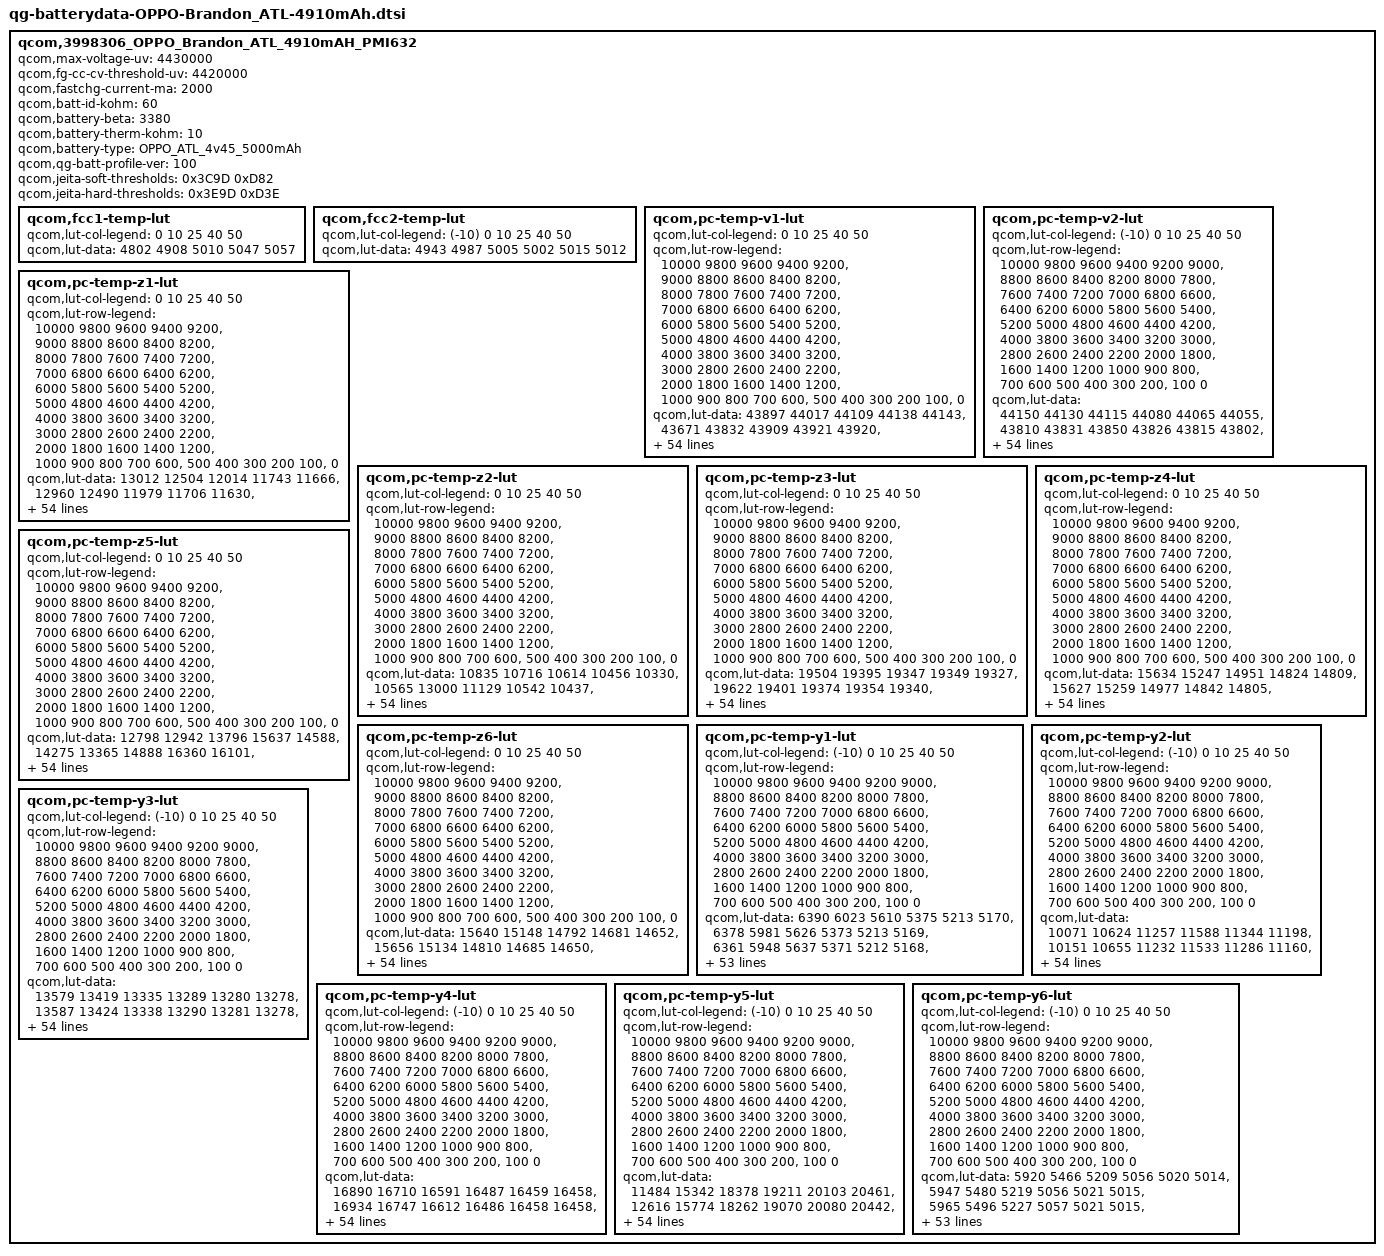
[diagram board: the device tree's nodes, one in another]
qcom,3998306_OPPO_Brandon_ATL_4910mAH_PMI632 {
    /* 3998306_OPPO_Brandon_ATL_4910mAH_PMI632_averaged_MasterSlave_May21th2019 */
    qcom,max-voltage-uv = <4430000>; //4430000
    qcom,fg-cc-cv-threshold-uv = <4420000>; //4420000
    qcom,fastchg-current-ma = <2000>;
    qcom,batt-id-kohm = <60>; // (68|300) + 5.1
    qcom,battery-beta = <3380>;
    qcom,battery-therm-kohm = <10>;
    qcom,battery-type = "OPPO_ATL_4v45_5000mAh";
    qcom,qg-batt-profile-ver = <100>;

    ////From the attached of 80-p3255-39_a
	qcom,jeita-soft-thresholds = <0x3C9D 0xD82>; //disable in kernel
	qcom,jeita-hard-thresholds = <0x3E9D 0xD3E>; //<(-8) 58>;Use SW disable,also Enable in kernel

	qcom,fcc1-temp-lut {
		qcom,lut-col-legend = <0 10 25 40 50>;
		qcom,lut-data = <4802 4908 5010 5047 5057>;
	};

	qcom,fcc2-temp-lut {
		qcom,lut-col-legend = <(-10) 0 10 25 40 50>;
		qcom,lut-data = <4943 4987 5005 5002 5015 5012>;
	};

	qcom,pc-temp-v1-lut {
		qcom,lut-col-legend = <0 10 25 40 50>;
		qcom,lut-row-legend = <10000 9800 9600 9400 9200>,
			<9000 8800 8600 8400 8200>,
			<8000 7800 7600 7400 7200>,
			<7000 6800 6600 6400 6200>,
			<6000 5800 5600 5400 5200>,
			<5000 4800 4600 4400 4200>,
			<4000 3800 3600 3400 3200>,
			<3000 2800 2600 2400 2200>,
			<2000 1800 1600 1400 1200>,
			<1000 900 800 700 600>,
			<500 400 300 200 100>,
			<0>;
		qcom,lut-data = <43897 44017 44109 44138 44143>,
			<43671 43832 43909 43921 43920>,
			<43440 43612 43712 43714 43713>,
			<43208 43382 43495 43507 43506>,
			<42974 43145 43268 43290 43291>,
			<42738 42901 43030 43063 43068>,
			<42501 42660 42789 42830 42839>,
			<42267 42421 42548 42595 42605>,
			<42037 42185 42309 42357 42367>,
			<41812 41951 42072 42119 42130>,
			<41593 41721 41838 41884 41895>,
			<41379 41497 41609 41651 41663>,
			<41167 41278 41383 41423 41437>,
			<40962 41070 41163 41199 41214>,
			<40761 40871 40951 40985 40997>,
			<40562 40678 40746 40779 40787>,
			<40364 40481 40549 40580 40584>,
			<40181 40289 40360 40389 40392>,
			<40017 40112 40176 40204 40206>,
			<39861 39956 40004 40027 40028>,
			<39704 39781 39836 39859 39862>,
			<39548 39536 39629 39668 39676>,
			<39379 39264 39346 39410 39430>,
			<39165 39067 39105 39162 39185>,
			<38949 38919 38969 39008 39023>,
			<38798 38803 38865 38895 38904>,
			<38686 38712 38765 38786 38790>,
			<38598 38637 38667 38677 38677>,
			<38531 38561 38575 38575 38572>,
			<38475 38488 38484 38481 38476>,
			<38424 38421 38400 38394 38389>,
			<38375 38360 38327 38315 38311>,
			<38331 38304 38261 38244 38241>,
			<38293 38253 38202 38178 38174>,
			<38259 38209 38152 38116 38105>,
			<38223 38167 38104 38057 38036>,
			<38188 38127 38056 37998 37967>,
			<38146 38086 38010 37940 37899>,
			<38080 38024 37948 37870 37819>,
			<37988 37930 37858 37776 37717>,
			<37883 37819 37751 37666 37600>,
			<37761 37696 37634 37548 37479>,
			<37621 37556 37499 37416 37347>,
			<37455 37387 37340 37260 37189>,
			<37310 37239 37191 37122 37054>,
			<37208 37134 37087 37032 36974>,
			<37167 37101 37060 37002 36947>,
			<37138 37083 37037 36984 36926>,
			<37104 37057 37016 36959 36898>,
			<37043 36991 36945 36874 36799>,
			<36816 36722 36668 36574 36486>,
			<36375 36275 36227 36129 36040>,
			<35799 35686 35651 35555 35463>,
			<35008 34873 34861 34768 34676>,
			<33707 33547 33627 33539 33445>,
			<30000 30000 30000 30000 30000>;
	};

	qcom,pc-temp-v2-lut {
		qcom,lut-col-legend = <(-10) 0 10 25 40 50>;
		qcom,lut-row-legend = <10000 9800 9600 9400 9200 9000>,
			<8800 8600 8400 8200 8000 7800>,
			<7600 7400 7200 7000 6800 6600>,
			<6400 6200 6000 5800 5600 5400>,
			<5200 5000 4800 4600 4400 4200>,
			<4000 3800 3600 3400 3200 3000>,
			<2800 2600 2400 2200 2000 1800>,
			<1600 1400 1200 1000 900 800>,
			<700 600 500 400 300 200>,
			<100 0>;
		qcom,lut-data = <44150 44130 44115 44080 44065 44055>,
			<43810 43831 43850 43826 43815 43802>,
			<43502 43554 43596 43580 43574 43559>,
			<43229 43301 43356 43345 43341 43326>,
			<42991 43074 43131 43121 43119 43105>,
			<42754 42844 42901 42892 42892 42881>,
			<42499 42603 42663 42655 42657 42648>,
			<42245 42359 42421 42414 42418 42411>,
			<42020 42114 42180 42176 42182 42175>,
			<41820 41867 41938 41938 41944 41939>,
			<41611 41624 41702 41705 41711 41707>,
			<41376 41377 41470 41473 41481 41477>,
			<41134 41143 41245 41247 41255 41251>,
			<40913 40954 41027 41028 41036 41032>,
			<40709 40794 40815 40815 40822 40818>,
			<40474 40606 40610 40609 40616 40612>,
			<40143 40355 40414 40410 40416 40414>,
			<39796 40089 40213 40217 40223 40223>,
			<39541 39850 39994 40034 40043 40044>,
			<39337 39622 39763 39854 39868 39869>,
			<39145 39404 39535 39646 39665 39668>,
			<38952 39191 39306 39392 39419 39428>,
			<38773 38994 39097 39155 39189 39201>,
			<38610 38817 38920 38971 39002 39014>,
			<38457 38654 38763 38813 38840 38851>,
			<38341 38494 38622 38676 38703 38712>,
			<38257 38326 38493 38556 38584 38593>,
			<38188 38190 38377 38449 38477 38484>,
			<38124 38100 38273 38350 38380 38384>,
			<38065 38031 38176 38258 38289 38290>,
			<38008 37977 38079 38174 38207 38206>,
			<37952 37932 37982 38095 38130 38130>,
			<37896 37889 37905 38021 38056 38055>,
			<37837 37842 37851 37955 37986 37985>,
			<37776 37794 37806 37889 37912 37908>,
			<37714 37743 37763 37815 37822 37806>,
			<37649 37687 37721 37731 37717 37680>,
			<37580 37624 37670 37646 37614 37566>,
			<37503 37553 37603 37562 37516 37469>,
			<37419 37470 37523 37478 37421 37378>,
			<37328 37372 37427 37392 37333 37289>,
			<37226 37258 37314 37299 37244 37195>,
			<37124 37132 37185 37183 37131 37079>,
			<37027 36990 37040 37052 37000 36947>,
			<36936 36848 36876 36921 36885 36834>,
			<36849 36747 36793 36872 36843 36794>,
			<36806 36708 36753 36853 36828 36781>,
			<36759 36675 36720 36831 36812 36763>,
			<36705 36632 36673 36797 36776 36726>,
			<36636 36552 36565 36703 36653 36583>,
			<36501 36345 36298 36401 36321 36229>,
			<36220 35916 35801 35905 35817 35724>,
			<35726 35275 35151 35266 35168 35068>,
			<34966 34334 34262 34402 34268 34160>,
			<33828 32877 32876 32999 32966 32811>,
			<32285 29186 27697 27990 28108 28121>;
	};

	qcom,pc-temp-z1-lut {
		qcom,lut-col-legend = <0 10 25 40 50>;
		qcom,lut-row-legend = <10000 9800 9600 9400 9200>,
			<9000 8800 8600 8400 8200>,
			<8000 7800 7600 7400 7200>,
			<7000 6800 6600 6400 6200>,
			<6000 5800 5600 5400 5200>,
			<5000 4800 4600 4400 4200>,
			<4000 3800 3600 3400 3200>,
			<3000 2800 2600 2400 2200>,
			<2000 1800 1600 1400 1200>,
			<1000 900 800 700 600>,
			<500 400 300 200 100>,
			<0>;
		qcom,lut-data = <13012 12504 12014 11743 11666>,
			<12960 12490 11979 11706 11630>,
			<12955 12465 11961 11693 11620>,
			<12965 12446 11951 11685 11612>,
			<12973 12435 11941 11678 11607>,
			<12960 12426 11930 11672 11603>,
			<12942 12411 11919 11667 11600>,
			<12933 12390 11909 11664 11600>,
			<12926 12377 11900 11661 11601>,
			<12917 12371 11896 11661 11602>,
			<12905 12362 11894 11662 11604>,
			<12890 12344 11892 11663 11605>,
			<12877 12325 11890 11664 11606>,
			<12863 12321 11889 11663 11605>,
			<12851 12322 11889 11663 11606>,
			<12837 12323 11890 11663 11607>,
			<12815 12321 11891 11663 11608>,
			<12802 12319 11892 11664 11609>,
			<12798 12315 11892 11665 11610>,
			<12797 12313 11892 11665 11611>,
			<12801 12315 11893 11666 11611>,
			<12813 12315 11893 11667 11612>,
			<12820 12315 11895 11668 11613>,
			<12814 12317 11897 11669 11615>,
			<12806 12322 11899 11671 11616>,
			<12806 12328 11901 11674 11618>,
			<12814 12334 11904 11677 11621>,
			<12819 12340 11909 11679 11624>,
			<12820 12341 11914 11682 11627>,
			<12822 12337 11918 11686 11629>,
			<12823 12335 11921 11690 11632>,
			<12826 12335 11923 11693 11634>,
			<12830 12337 11925 11696 11637>,
			<12839 12339 11928 11699 11640>,
			<12853 12344 11935 11702 11643>,
			<12862 12350 11941 11706 11646>,
			<12870 12359 11945 11709 11649>,
			<12875 12371 11947 11713 11652>,
			<12879 12377 11950 11716 11654>,
			<12881 12382 11955 11719 11656>,
			<12886 12387 11961 11722 11659>,
			<12908 12390 11969 11725 11661>,
			<12918 12395 11978 11729 11663>,
			<12902 12407 11985 11731 11665>,
			<12921 12414 11992 11733 11668>,
			<12912 12400 11993 11737 11668>,
			<12927 12399 11996 11736 11668>,
			<12929 12407 11995 11736 11669>,
			<12934 12405 12002 11739 11670>,
			<12910 12418 12000 11742 11674>,
			<12961 12420 12005 11746 11677>,
			<12942 12438 12016 11753 11683>,
			<12954 12448 12029 11760 11690>,
			<12983 12480 12054 11773 11699>,
			<12983 12480 12054 11773 11699>,
			<12983 12480 12054 11773 11699>;
	};

	qcom,pc-temp-z2-lut {
		qcom,lut-col-legend = <0 10 25 40 50>;
		qcom,lut-row-legend = <10000 9800 9600 9400 9200>,
			<9000 8800 8600 8400 8200>,
			<8000 7800 7600 7400 7200>,
			<7000 6800 6600 6400 6200>,
			<6000 5800 5600 5400 5200>,
			<5000 4800 4600 4400 4200>,
			<4000 3800 3600 3400 3200>,
			<3000 2800 2600 2400 2200>,
			<2000 1800 1600 1400 1200>,
			<1000 900 800 700 600>,
			<500 400 300 200 100>,
			<0>;
		qcom,lut-data = <10835 10716 10614 10456 10330>,
			<10565 13000 11129 10542 10437>,
			<10459 11886 11760 10548 10369>,
			<10433 11134 11296 10589 10446>,
			<10411 10782 10971 10611 10515>,
			<10378 10572 10762 10594 10526>,
			<10345 10527 10642 10565 10518>,
			<10325 10503 10621 10538 10492>,
			<10308 10486 10607 10511 10453>,
			<10300 10471 10589 10498 10431>,
			<10332 10463 10569 10493 10421>,
			<10378 10461 10563 10490 10415>,
			<10379 10462 10573 10501 10415>,
			<10336 10475 10587 10522 10422>,
			<10310 10591 10653 10522 10423>,
			<10317 10701 10910 10483 10419>,
			<10328 10683 11051 10450 10411>,
			<10350 10607 10876 10461 10387>,
			<10449 10585 10659 10487 10359>,
			<10540 10600 10644 10484 10362>,
			<10531 10618 10662 10452 10392>,
			<10481 10637 10682 10436 10414>,
			<10463 10652 10709 10490 10422>,
			<10468 10649 10722 10554 10431>,
			<10474 10620 10703 10549 10494>,
			<10481 10600 10675 10520 10712>,
			<10490 10607 10681 10522 10850>,
			<10499 10621 10729 10652 10869>,
			<10504 10626 10758 10760 10820>,
			<10509 10627 10756 10732 10716>,
			<10516 10629 10750 10659 10580>,
			<10524 10632 10740 10607 10464>,
			<10532 10637 10721 10566 10344>,
			<10539 10643 10710 10543 10284>,
			<10546 10653 10714 10542 10307>,
			<10554 10666 10724 10553 10358>,
			<10563 10677 10744 10579 10406>,
			<10574 10689 10780 10637 10459>,
			<10588 10704 10811 10687 10506>,
			<10606 10726 10834 10721 10546>,
			<10622 10743 10853 10749 10579>,
			<10633 10749 10869 10773 10612>,
			<10650 10755 10882 10791 10647>,
			<10693 10775 10890 10799 10704>,
			<10950 10935 10933 10786 10692>,
			<10883 11063 10981 10672 10538>,
			<10860 11058 10937 10650 10553>,
			<10700 11347 10948 10653 10560>,
			<10450 11491 10955 10678 10609>,
			<10429 11570 11090 10746 10612>,
			<10374 11449 11079 10622 10429>,
			<10226 11407 11035 10453 10299>,
			<9978 11225 11042 10407 10256>,
			<9902 10923 10973 10354 10171>,
			<9902 10923 10973 10354 10171>,
			<9902 10923 10973 10354 10171>;
	};

	qcom,pc-temp-z3-lut {
		qcom,lut-col-legend = <0 10 25 40 50>;
		qcom,lut-row-legend = <10000 9800 9600 9400 9200>,
			<9000 8800 8600 8400 8200>,
			<8000 7800 7600 7400 7200>,
			<7000 6800 6600 6400 6200>,
			<6000 5800 5600 5400 5200>,
			<5000 4800 4600 4400 4200>,
			<4000 3800 3600 3400 3200>,
			<3000 2800 2600 2400 2200>,
			<2000 1800 1600 1400 1200>,
			<1000 900 800 700 600>,
			<500 400 300 200 100>,
			<0>;
		qcom,lut-data = <19504 19395 19347 19349 19327>,
			<19622 19401 19374 19354 19340>,
			<19680 19468 19391 19377 19361>,
			<19713 19510 19438 19387 19374>,
			<19730 19542 19458 19395 19382>,
			<19738 19563 19457 19402 19387>,
			<19743 19567 19453 19406 19390>,
			<19744 19568 19453 19407 19393>,
			<19737 19568 19454 19407 19395>,
			<19730 19567 19453 19407 19395>,
			<19731 19566 19447 19403 19392>,
			<19734 19562 19440 19399 19387>,
			<19730 19556 19432 19396 19383>,
			<19716 19552 19426 19393 19380>,
			<19704 19550 19426 19390 19376>,
			<19702 19548 19435 19382 19373>,
			<19701 19541 19439 19375 19370>,
			<19702 19527 19428 19372 19366>,
			<19696 19519 19414 19370 19363>,
			<19685 19514 19411 19367 19359>,
			<19678 19512 19409 19362 19354>,
			<19668 19525 19410 19360 19350>,
			<19667 19547 19418 19362 19349>,
			<19682 19550 19424 19363 19348>,
			<19699 19542 19416 19359 19347>,
			<19701 19533 19401 19347 19352>,
			<19696 19526 19398 19344 19361>,
			<19690 19520 19400 19363 19385>,
			<19683 19520 19405 19385 19402>,
			<19676 19522 19417 19392 19400>,
			<19669 19525 19431 19397 19393>,
			<19664 19526 19433 19397 19386>,
			<19659 19527 19432 19391 19376>,
			<19654 19527 19430 19384 19367>,
			<19649 19525 19426 19378 19359>,
			<19644 19523 19420 19372 19353>,
			<19640 19520 19416 19366 19348>,
			<19636 19515 19412 19362 19345>,
			<19632 19511 19408 19359 19343>,
			<19626 19506 19404 19357 19344>,
			<19620 19501 19400 19355 19344>,
			<19610 19497 19400 19357 19347>,
			<19597 19492 19399 19362 19353>,
			<19577 19484 19395 19363 19359>,
			<19456 19451 19384 19359 19358>,
			<19332 19426 19375 19342 19340>,
			<19325 19423 19370 19341 19331>,
			<19304 19349 19369 19334 19326>,
			<19282 19317 19359 19329 19323>,
			<19281 19307 19344 19328 19327>,
			<19281 19339 19358 19356 19352>,
			<19285 19314 19355 19363 19356>,
			<19291 19309 19333 19356 19352>,
			<19302 19316 19333 19355 19353>,
			<19302 19316 19333 19355 19353>,
			<19302 19316 19333 19355 19353>;
	};

	qcom,pc-temp-z4-lut {
		qcom,lut-col-legend = <0 10 25 40 50>;
		qcom,lut-row-legend = <10000 9800 9600 9400 9200>,
			<9000 8800 8600 8400 8200>,
			<8000 7800 7600 7400 7200>,
			<7000 6800 6600 6400 6200>,
			<6000 5800 5600 5400 5200>,
			<5000 4800 4600 4400 4200>,
			<4000 3800 3600 3400 3200>,
			<3000 2800 2600 2400 2200>,
			<2000 1800 1600 1400 1200>,
			<1000 900 800 700 600>,
			<500 400 300 200 100>,
			<0>;
		qcom,lut-data = <15634 15247 14951 14824 14809>,
			<15627 15259 14977 14842 14805>,
			<15583 15207 14956 14864 14833>,
			<15444 15143 14893 14845 14820>,
			<15302 15068 14860 14823 14804>,
			<15206 15001 14843 14802 14787>,
			<15126 14947 14829 14782 14771>,
			<15065 14902 14809 14765 14755>,
			<15019 14865 14782 14749 14740>,
			<14975 14835 14761 14734 14727>,
			<14925 14810 14745 14721 14717>,
			<14880 14790 14734 14710 14708>,
			<14859 14773 14727 14703 14703>,
			<14847 14755 14721 14696 14698>,
			<14836 14730 14708 14692 14693>,
			<14821 14713 14683 14689 14688>,
			<14804 14717 14670 14687 14684>,
			<14786 14729 14678 14681 14679>,
			<14762 14731 14690 14675 14676>,
			<14745 14722 14691 14674 14675>,
			<14744 14716 14690 14677 14677>,
			<14747 14740 14699 14683 14680>,
			<14752 14788 14765 14739 14731>,
			<14777 14816 14817 14800 14793>,
			<14814 14833 14821 14807 14796>,
			<14829 14840 14821 14807 14780>,
			<14836 14832 14819 14805 14761>,
			<14838 14817 14802 14773 14725>,
			<14833 14802 14779 14735 14695>,
			<14821 14786 14755 14714 14688>,
			<14810 14771 14731 14698 14684>,
			<14799 14760 14718 14689 14681>,
			<14789 14750 14710 14683 14678>,
			<14780 14743 14706 14681 14676>,
			<14771 14738 14704 14681 14675>,
			<14761 14734 14702 14681 14675>,
			<14751 14730 14703 14681 14675>,
			<14742 14726 14704 14683 14675>,
			<14738 14726 14705 14685 14676>,
			<14735 14726 14712 14694 14686>,
			<14732 14726 14717 14703 14697>,
			<14727 14718 14712 14699 14693>,
			<14722 14707 14700 14689 14683>,
			<14718 14700 14697 14689 14682>,
			<14768 14687 14686 14684 14677>,
			<14864 14673 14665 14671 14664>,
			<14869 14670 14660 14665 14664>,
			<14888 14741 14647 14655 14653>,
			<14903 14770 14645 14641 14635>,
			<14895 14777 14659 14641 14631>,
			<14899 14751 14664 14646 14647>,
			<14912 14786 14674 14650 14654>,
			<14917 14796 14701 14659 14660>,
			<14930 14798 14703 14663 14661>,
			<14930 14798 14703 14663 14661>,
			<14930 14798 14703 14663 14661>;
	};

	qcom,pc-temp-z5-lut {
		qcom,lut-col-legend = <0 10 25 40 50>;
		qcom,lut-row-legend = <10000 9800 9600 9400 9200>,
			<9000 8800 8600 8400 8200>,
			<8000 7800 7600 7400 7200>,
			<7000 6800 6600 6400 6200>,
			<6000 5800 5600 5400 5200>,
			<5000 4800 4600 4400 4200>,
			<4000 3800 3600 3400 3200>,
			<3000 2800 2600 2400 2200>,
			<2000 1800 1600 1400 1200>,
			<1000 900 800 700 600>,
			<500 400 300 200 100>,
			<0>;
		qcom,lut-data = <12798 12942 13796 15637 14588>,
			<14275 13365 14888 16360 16101>,
			<15196 14536 15383 17699 17817>,
			<15794 15437 17125 18608 19308>,
			<16278 16557 18339 19549 20489>,
			<16771 17723 19034 20339 21135>,
			<17251 18495 19644 20928 21726>,
			<17607 19149 20341 21344 22526>,
			<17828 19877 21064 21818 23538>,
			<18098 20760 21627 22421 24399>,
			<18795 21675 22020 23251 25081>,
			<19712 22508 22038 24062 25645>,
			<20260 23343 22108 25033 26085>,
			<20630 24489 22413 26082 26465>,
			<21087 26586 24167 26273 26973>,
			<22176 28320 29862 25478 27821>,
			<24276 28380 33051 24820 28817>,
			<26009 27508 30477 25750 30098>,
			<27514 27182 27200 27317 31254>,
			<28392 27763 27387 27684 31372>,
			<28481 29106 28455 27519 30819>,
			<30138 39389 30165 27183 29924>,
			<33137 53688 33282 26448 26972>,
			<43048 54874 35123 25278 23335>,
			<53808 44872 30867 22602 21196>,
			<54636 35515 23347 18271 19482>,
			<50158 31152 21166 16964 19440>,
			<45350 28323 20755 18584 24153>,
			<41829 28012 20734 21029 28881>,
			<38812 28876 23113 23745 29958>,
			<37459 30190 27497 26767 30518>,
			<36728 32170 30895 28719 30366>,
			<36319 34805 33961 30118 28708>,
			<36171 37190 36143 30948 27552>,
			<36097 39660 37766 31431 27653>,
			<36188 41185 38758 31743 27838>,
			<37024 41652 38528 31577 27874>,
			<38227 41834 37421 30613 27782>,
			<39550 41441 35995 29371 27586>,
			<41039 39972 33140 27249 26236>,
			<41440 38566 30657 25477 24795>,
			<38670 37745 30444 25721 25141>,
			<35221 36847 30542 26551 26594>,
			<32662 35525 28666 26893 29501>,
			<22509 31732 28076 26247 30327>,
			<13314 29628 29688 22164 23207>,
			<13063 28271 27838 22344 19754>,
			<12473 16200 29423 21721 20327>,
			<12105 13582 25742 23675 24032>,
			<12133 13292 20278 22877 28764>,
			<12186 15204 21212 27085 28171>,
			<12086 13307 19514 25872 24750>,
			<12036 12958 15331 20607 20524>,
			<12134 13020 14962 18701 18604>,
			<12134 13020 14962 18701 18604>,
			<12134 13020 14962 18701 18604>;
	};

	qcom,pc-temp-z6-lut {
		qcom,lut-col-legend = <0 10 25 40 50>;
		qcom,lut-row-legend = <10000 9800 9600 9400 9200>,
			<9000 8800 8600 8400 8200>,
			<8000 7800 7600 7400 7200>,
			<7000 6800 6600 6400 6200>,
			<6000 5800 5600 5400 5200>,
			<5000 4800 4600 4400 4200>,
			<4000 3800 3600 3400 3200>,
			<3000 2800 2600 2400 2200>,
			<2000 1800 1600 1400 1200>,
			<1000 900 800 700 600>,
			<500 400 300 200 100>,
			<0>;
		qcom,lut-data = <15640 15148 14792 14681 14652>,
			<15656 15134 14810 14685 14650>,
			<15641 15130 14805 14702 14669>,
			<15572 15116 14799 14698 14669>,
			<15495 15084 14791 14694 14669>,
			<15440 15052 14782 14689 14665>,
			<15392 15023 14772 14682 14659>,
			<15351 14994 14761 14675 14654>,
			<15316 14970 14749 14668 14649>,
			<15284 14950 14738 14661 14644>,
			<15256 14933 14727 14654 14638>,
			<15231 14918 14718 14647 14632>,
			<15210 14904 14710 14642 14627>,
			<15191 14891 14704 14638 14623>,
			<15175 14879 14699 14633 14619>,
			<15161 14869 14693 14628 14615>,
			<15149 14865 14689 14623 14611>,
			<15137 14861 14686 14619 14607>,
			<15122 14857 14683 14615 14603>,
			<15109 14850 14682 14613 14601>,
			<15107 14847 14681 14612 14599>,
			<15106 14866 14686 14612 14598>,
			<15106 14898 14719 14637 14619>,
			<15125 14911 14745 14665 14646>,
			<15152 14915 14743 14667 14648>,
			<15160 14916 14737 14662 14644>,
			<15161 14912 14732 14658 14641>,
			<15162 14903 14727 14655 14639>,
			<15158 14897 14723 14652 14636>,
			<15150 14893 14720 14648 14632>,
			<15144 14889 14717 14644 14628>,
			<15138 14886 14714 14640 14623>,
			<15133 14883 14710 14635 14616>,
			<15128 14881 14707 14631 14611>,
			<15124 14879 14705 14627 14607>,
			<15120 14878 14703 14625 14603>,
			<15117 14876 14702 14622 14601>,
			<15115 14875 14700 14620 14599>,
			<15116 14875 14700 14620 14598>,
			<15118 14876 14702 14623 14603>,
			<15120 14876 14704 14627 14608>,
			<15120 14874 14702 14626 14608>,
			<15119 14871 14698 14625 14607>,
			<15116 14869 14696 14625 14610>,
			<15087 14855 14688 14622 14608>,
			<15072 14840 14676 14608 14593>,
			<15071 14838 14672 14605 14589>,
			<15069 14831 14666 14597 14581>,
			<15069 14829 14660 14588 14571>,
			<15071 14831 14661 14588 14572>,
			<15079 14841 14672 14606 14593>,
			<15096 14849 14677 14613 14600>,
			<15113 14858 14681 14615 14603>,
			<15144 14874 14686 14619 14607>,
			<15144 14874 14686 14619 14607>,
			<15144 14874 14686 14619 14607>;
	};

	qcom,pc-temp-y1-lut {
		qcom,lut-col-legend = <(-10) 0 10 25 40 50>;
		qcom,lut-row-legend = <10000 9800 9600 9400 9200 9000>,
			<8800 8600 8400 8200 8000 7800>,
			<7600 7400 7200 7000 6800 6600>,
			<6400 6200 6000 5800 5600 5400>,
			<5200 5000 4800 4600 4400 4200>,
			<4000 3800 3600 3400 3200 3000>,
			<2800 2600 2400 2200 2000 1800>,
			<1600 1400 1200 1000 900 800>,
			<700 600 500 400 300 200>,
			<100 0>;
		qcom,lut-data = <6390 6023 5610 5375 5213 5170>,
			<6378 5981 5626 5373 5213 5169>,
			<6361 5948 5637 5371 5212 5168>,
			<6345 5923 5644 5367 5212 5166>,
			<6334 5908 5647 5364 5211 5165>,
			<6333 5904 5648 5362 5210 5164>,
			<6344 5915 5643 5360 5209 5164>,
			<6355 5929 5637 5358 5208 5164>,
			<6352 5929 5637 5357 5207 5164>,
			<6335 5918 5638 5357 5205 5164>,
			<6326 5909 5638 5357 5205 5164>,
			<6336 5902 5634 5357 5205 5164>,
			<6350 5898 5630 5356 5205 5164>,
			<6354 5900 5629 5355 5205 5165>,
			<6361 5906 5631 5354 5205 5165>,
			<6369 5909 5632 5354 5204 5165>,
			<6365 5903 5633 5356 5205 5165>,
			<6357 5896 5634 5358 5205 5166>,
			<6350 5899 5633 5358 5206 5166>,
			<6326 5910 5631 5357 5206 5166>,
			<6313 5915 5631 5357 5207 5167>,
			<6321 5913 5635 5358 5208 5167>,
			<6331 5910 5638 5359 5208 5168>,
			<6327 5908 5639 5361 5209 5169>,
			<6315 5906 5640 5363 5211 5170>,
			<6310 5908 5642 5365 5212 5172>,
			<6326 5915 5645 5367 5214 5173>,
			<6348 5920 5647 5369 5216 5175>,
			<6349 5924 5646 5373 5217 5176>,
			<6337 5924 5643 5376 5219 5178>,
			<6332 5920 5644 5378 5221 5180>,
			<6340 5909 5653 5380 5224 5182>,
			<6347 5903 5660 5383 5226 5184>,
			<6343 5915 5656 5387 5228 5185>,
			<6331 5935 5650 5392 5230 5187>,
			<6326 5942 5647 5394 5232 5189>,
			<6319 5941 5646 5395 5233 5190>,
			<6312 5936 5645 5395 5234 5191>,
			<6314 5930 5649 5395 5235 5192>,
			<6324 5925 5654 5395 5236 5194>,
			<6330 5927 5660 5399 5237 5194>,
			<6330 5938 5670 5403 5239 5194>,
			<6329 5932 5676 5404 5240 5195>,
			<6352 5922 5676 5407 5241 5196>,
			<6341 5966 5671 5411 5244 5198>,
			<6352 5978 5691 5415 5246 5201>,
			<6356 5977 5687 5417 5248 5200>,
			<6369 5963 5676 5416 5248 5200>,
			<6364 5985 5674 5420 5247 5201>,
			<6348 5954 5693 5417 5247 5202>,
			<6385 5978 5697 5420 5249 5205>,
			<6458 6002 5696 5427 5253 5207>,
			<6553 6069 5723 5439 5257 5212>,
			<6626 6142 5763 5452 5265 5219>,
			<6626 6142 5763 5452 5265 5219>,
			<6626 6142 5763 5452 5265 5219>;
	};

	qcom,pc-temp-y2-lut {
		qcom,lut-col-legend = <(-10) 0 10 25 40 50>;
		qcom,lut-row-legend = <10000 9800 9600 9400 9200 9000>,
			<8800 8600 8400 8200 8000 7800>,
			<7600 7400 7200 7000 6800 6600>,
			<6400 6200 6000 5800 5600 5400>,
			<5200 5000 4800 4600 4400 4200>,
			<4000 3800 3600 3400 3200 3000>,
			<2800 2600 2400 2200 2000 1800>,
			<1600 1400 1200 1000 900 800>,
			<700 600 500 400 300 200>,
			<100 0>;
		qcom,lut-data = <10071 10624 11257 11588 11344 11198>,
			<10151 10655 11232 11533 11286 11160>,
			<10238 10700 11207 11472 11224 11104>,
			<10322 10745 11185 11413 11163 11045>,
			<10392 10782 11163 11364 11112 10996>,
			<10438 10798 11144 11333 11074 10973>,
			<10458 10801 11126 11318 11047 10968>,
			<10475 10801 11110 11307 11026 10964>,
			<10530 10800 11097 11290 11009 10951>,
			<10659 10798 11086 11267 10990 10925>,
			<10728 10803 11082 11253 10980 10915>,
			<10725 10889 11089 11248 10978 10922>,
			<10720 10989 11103 11248 10981 10930>,
			<10732 11000 11131 11260 11000 10925>,
			<10782 10994 11184 11283 11042 10912>,
			<10802 10998 11237 11306 11061 10918>,
			<10354 11066 11295 11345 11079 10972>,
			<9780 11146 11342 11393 11106 11041>,
			<9700 11181 11367 11462 11182 11104>,
			<9694 11204 11385 11545 11307 11171>,
			<9690 11226 11392 11562 11365 11219>,
			<9687 11252 11396 11523 11379 11261>,
			<9684 11270 11400 11488 11376 11276>,
			<9681 11248 11422 11487 11328 11240>,
			<9678 11188 11458 11499 11270 11195>,
			<9675 11153 11476 11522 11277 11195>,
			<9674 11116 11487 11577 11332 11227>,
			<9673 11089 11494 11621 11378 11265>,
			<9672 10911 11502 11638 11434 11308>,
			<9671 10536 11509 11651 11497 11349>,
			<9669 10404 11508 11666 11508 11365>,
			<9668 10349 11501 11696 11495 11370>,
			<9667 10267 11494 11721 11491 11390>,
			<9666 10011 11474 11741 11541 11526>,
			<9666 9746 11440 11756 11600 11671>,
			<9665 9702 11407 11737 11589 11614>,
			<9665 9688 11370 11677 11536 11431>,
			<9664 9680 11322 11645 11491 11364>,
			<9664 9674 11235 11637 11447 11383>,
			<9664 9670 11122 11631 11414 11407>,
			<9663 9667 11018 11626 11423 11357>,
			<9663 9665 10914 11628 11452 11264>,
			<9663 9664 10802 11612 11474 11285>,
			<9662 9663 10647 11558 11393 11284>,
			<9661 9662 10298 11527 11320 11180>,
			<9660 9660 9919 11459 11180 11026>,
			<9660 9660 9887 11451 11179 10996>,
			<9659 9659 9802 11424 11202 11016>,
			<9658 9658 9739 11437 11213 11096>,
			<9656 9657 9699 11420 11205 11021>,
			<9653 9656 9683 11398 11148 10922>,
			<9650 9653 9668 11317 11017 10873>,
			<9649 9650 9659 11207 10942 10787>,
			<9648 9649 9654 11102 10808 10591>,
			<9648 9649 9654 11102 10808 10591>,
			<9648 9649 9654 11102 10808 10591>;
	};

	qcom,pc-temp-y3-lut {
		qcom,lut-col-legend = <(-10) 0 10 25 40 50>;
		qcom,lut-row-legend = <10000 9800 9600 9400 9200 9000>,
			<8800 8600 8400 8200 8000 7800>,
			<7600 7400 7200 7000 6800 6600>,
			<6400 6200 6000 5800 5600 5400>,
			<5200 5000 4800 4600 4400 4200>,
			<4000 3800 3600 3400 3200 3000>,
			<2800 2600 2400 2200 2000 1800>,
			<1600 1400 1200 1000 900 800>,
			<700 600 500 400 300 200>,
			<100 0>;
		qcom,lut-data = <13579 13419 13335 13289 13280 13278>,
			<13587 13424 13338 13290 13281 13278>,
			<13592 13429 13341 13292 13281 13278>,
			<13594 13434 13343 13293 13282 13279>,
			<13595 13438 13346 13295 13283 13279>,
			<13595 13441 13348 13295 13283 13280>,
			<13586 13443 13349 13295 13284 13281>,
			<13574 13444 13351 13295 13284 13281>,
			<13574 13443 13351 13296 13284 13282>,
			<13580 13438 13352 13297 13285 13283>,
			<13583 13433 13352 13298 13285 13283>,
			<13546 13427 13351 13297 13285 13283>,
			<13496 13422 13351 13297 13286 13283>,
			<13490 13416 13349 13297 13287 13284>,
			<13495 13403 13346 13300 13288 13284>,
			<13497 13398 13345 13301 13288 13285>,
			<13486 13400 13345 13302 13289 13286>,
			<13471 13401 13346 13302 13289 13288>,
			<13464 13396 13344 13303 13290 13289>,
			<13461 13387 13340 13304 13293 13290>,
			<13458 13378 13336 13304 13293 13289>,
			<13458 13372 13331 13300 13289 13286>,
			<13458 13365 13327 13296 13284 13282>,
			<13453 13358 13325 13293 13282 13280>,
			<13441 13352 13323 13291 13281 13279>,
			<13437 13346 13321 13291 13280 13278>,
			<13448 13339 13319 13290 13280 13278>,
			<13468 13334 13317 13290 13280 13278>,
			<13488 13331 13316 13290 13280 13278>,
			<13514 13329 13315 13290 13280 13277>,
			<13542 13334 13313 13290 13280 13277>,
			<13572 13341 13310 13290 13279 13277>,
			<13604 13350 13309 13290 13279 13277>,
			<13639 13363 13310 13290 13280 13279>,
			<13677 13380 13312 13290 13281 13280>,
			<13718 13401 13314 13290 13281 13280>,
			<13763 13426 13317 13289 13280 13277>,
			<13808 13456 13319 13288 13280 13277>,
			<13849 13493 13321 13288 13279 13278>,
			<13888 13536 13323 13287 13279 13279>,
			<13923 13585 13326 13288 13280 13280>,
			<13954 13642 13329 13289 13282 13281>,
			<13989 13705 13334 13289 13282 13281>,
			<14031 13776 13339 13289 13280 13279>,
			<14088 13809 13336 13286 13277 13276>,
			<14111 13880 13331 13292 13283 13283>,
			<14192 13958 13349 13293 13286 13286>,
			<14288 14052 13368 13296 13290 13288>,
			<14426 14135 13397 13301 13292 13289>,
			<14662 14263 13432 13303 13290 13286>,
			<15397 14448 13482 13299 13286 13284>,
			<17611 15058 13594 13301 13286 13285>,
			<24133 17728 13919 13304 13290 13288>,
			<45011 29791 14833 13314 13297 13294>,
			<45011 29791 14833 13314 13297 13294>,
			<45011 29791 14833 13314 13297 13294>;
	};

	qcom,pc-temp-y4-lut {
		qcom,lut-col-legend = <(-10) 0 10 25 40 50>;
		qcom,lut-row-legend = <10000 9800 9600 9400 9200 9000>,
			<8800 8600 8400 8200 8000 7800>,
			<7600 7400 7200 7000 6800 6600>,
			<6400 6200 6000 5800 5600 5400>,
			<5200 5000 4800 4600 4400 4200>,
			<4000 3800 3600 3400 3200 3000>,
			<2800 2600 2400 2200 2000 1800>,
			<1600 1400 1200 1000 900 800>,
			<700 600 500 400 300 200>,
			<100 0>;
		qcom,lut-data = <16890 16710 16591 16487 16459 16458>,
			<16934 16747 16612 16486 16458 16458>,
			<17009 16812 16639 16485 16458 16459>,
			<17090 16882 16665 16486 16458 16459>,
			<17155 16938 16684 16486 16459 16459>,
			<17181 16958 16691 16487 16459 16459>,
			<17177 16955 16687 16489 16461 16459>,
			<17170 16949 16681 16492 16462 16459>,
			<17161 16948 16678 16494 16464 16460>,
			<17149 16948 16676 16497 16467 16461>,
			<17143 16947 16675 16501 16470 16463>,
			<17196 16947 16681 16508 16474 16466>,
			<17269 16950 16692 16517 16478 16469>,
			<17268 16983 16709 16525 16483 16473>,
			<17216 17062 16735 16532 16488 16478>,
			<17157 17089 16754 16541 16494 16483>,
			<17088 17020 16768 16557 16502 16487>,
			<17015 16930 16775 16576 16513 16492>,
			<16966 16883 16763 16596 16530 16505>,
			<16929 16847 16727 16615 16549 16523>,
			<16888 16810 16690 16614 16550 16526>,
			<16835 16771 16644 16564 16523 16508>,
			<16787 16735 16608 16514 16495 16488>,
			<16763 16704 16587 16494 16477 16473>,
			<16747 16676 16572 16481 16464 16461>,
			<16742 16640 16563 16480 16462 16460>,
			<16742 16588 16557 16481 16464 16460>,
			<16742 16558 16552 16482 16466 16461>,
			<16741 16567 16548 16487 16471 16465>,
			<16737 16587 16544 16493 16478 16473>,
			<16736 16600 16534 16500 16486 16481>,
			<16739 16609 16516 16506 16497 16490>,
			<16744 16620 16507 16512 16505 16497>,
			<16749 16639 16511 16517 16509 16503>,
			<16754 16661 16520 16521 16511 16506>,
			<16759 16676 16532 16517 16506 16500>,
			<16763 16689 16550 16502 16490 16483>,
			<16766 16698 16566 16489 16479 16474>,
			<16766 16704 16582 16481 16471 16471>,
			<16764 16708 16595 16476 16467 16470>,
			<16761 16703 16604 16479 16470 16473>,
			<16753 16691 16608 16487 16473 16478>,
			<16746 16683 16610 16490 16471 16475>,
			<16743 16673 16610 16489 16461 16460>,
			<16749 16650 16587 16474 16449 16444>,
			<16739 16649 16623 16479 16457 16459>,
			<16740 16663 16616 16490 16475 16486>,
			<16754 16678 16639 16506 16505 16521>,
			<16774 16702 16670 16531 16537 16546>,
			<16787 16728 16703 16544 16524 16526>,
			<16864 16737 16710 16510 16476 16473>,
			<17203 16745 16711 16499 16467 16467>,
			<18784 17262 16755 16517 16470 16468>,
			<33903 23428 16980 16554 16486 16482>,
			<33903 23428 16980 16554 16486 16482>,
			<33903 23428 16980 16554 16486 16482>;
	};

	qcom,pc-temp-y5-lut {
		qcom,lut-col-legend = <(-10) 0 10 25 40 50>;
		qcom,lut-row-legend = <10000 9800 9600 9400 9200 9000>,
			<8800 8600 8400 8200 8000 7800>,
			<7600 7400 7200 7000 6800 6600>,
			<6400 6200 6000 5800 5600 5400>,
			<5200 5000 4800 4600 4400 4200>,
			<4000 3800 3600 3400 3200 3000>,
			<2800 2600 2400 2200 2000 1800>,
			<1600 1400 1200 1000 900 800>,
			<700 600 500 400 300 200>,
			<100 0>;
		qcom,lut-data = <11484 15342 18378 19211 20103 20461>,
			<12616 15774 18262 19070 20080 20442>,
			<13955 16190 18174 18883 19907 20224>,
			<15286 16577 18115 18661 19624 19909>,
			<16388 16923 18085 18411 19269 19605>,
			<17043 17213 18088 18139 18879 19413>,
			<17283 17502 18143 17464 18376 19215>,
			<17470 17712 18202 16689 17828 19034>,
			<18207 17620 18115 16447 17360 18911>,
			<20172 17162 17741 16357 16883 18542>,
			<21216 16780 17357 16191 16452 18123>,
			<19638 16301 17005 15533 16024 17382>,
			<17517 15865 16638 14923 15667 16593>,
			<18144 16069 16181 14928 15492 16089>,
			<21827 17008 15654 15045 15474 15689>,
			<23732 17816 15591 15098 15492 15618>,
			<20068 19160 17031 15067 15146 15910>,
			<15410 20462 18940 15109 14846 16187>,
			<14935 21020 20390 15997 15178 16210>,
			<15291 21451 21709 18084 16027 16210>,
			<15505 21915 22401 19807 17172 16709>,
			<15505 22447 22815 21519 19181 18716>,
			<15398 22906 23002 22413 20340 20143>,
			<14777 23253 23125 22077 20161 20327>,
			<13188 23563 23321 21447 19815 20326>,
			<12470 23574 23324 21053 19571 20103>,
			<12466 21551 23088 20720 18746 19319>,
			<12466 19418 22962 20564 18091 18343>,
			<12542 17096 23586 20650 17901 17162>,
			<12789 14273 24459 20830 17705 16159>,
			<12992 13918 24198 20999 17487 16045>,
			<13118 14250 22300 21208 17171 16135>,
			<13226 14515 20896 21509 17103 16370>,
			<13326 14408 20495 22325 18134 17993>,
			<13420 14248 20306 23256 19479 19751>,
			<13542 14353 20382 23555 20234 19806>,
			<13773 14570 20558 23518 20851 19211>,
			<13961 14739 20593 23196 21034 19007>,
			<14001 14866 19940 22109 20347 20532>,
			<14027 14959 19187 21013 19572 22085>,
			<14008 14900 18959 20421 20128 22282>,
			<13686 14698 18845 19880 21620 22341>,
			<13363 14532 18729 19348 22066 23042>,
			<13115 14361 18720 19292 20718 22916>,
			<12842 14126 17043 18749 17856 18067>,
			<12710 13844 14677 20538 18614 19648>,
			<12990 13581 14673 18976 18517 18533>,
			<12933 13813 14568 18630 18660 17399>,
			<13043 13898 14763 19512 18084 16897>,
			<13551 14129 14789 19884 17636 16431>,
			<13029 14199 14706 19923 18001 16891>,
			<11262 13479 14289 21615 18087 17171>,
			<9719 11015 14119 21187 19631 17420>,
			<8979 9361 12888 23080 24574 22968>,
			<8979 9361 12888 23080 24574 22968>,
			<8979 9361 12888 23080 24574 22968>;
	};

	qcom,pc-temp-y6-lut {
		qcom,lut-col-legend = <(-10) 0 10 25 40 50>;
		qcom,lut-row-legend = <10000 9800 9600 9400 9200 9000>,
			<8800 8600 8400 8200 8000 7800>,
			<7600 7400 7200 7000 6800 6600>,
			<6400 6200 6000 5800 5600 5400>,
			<5200 5000 4800 4600 4400 4200>,
			<4000 3800 3600 3400 3200 3000>,
			<2800 2600 2400 2200 2000 1800>,
			<1600 1400 1200 1000 900 800>,
			<700 600 500 400 300 200>,
			<100 0>;
		qcom,lut-data = <5920 5466 5209 5056 5020 5014>,
			<5947 5480 5219 5056 5021 5015>,
			<5965 5496 5227 5057 5021 5015>,
			<5976 5510 5233 5058 5022 5016>,
			<5982 5520 5236 5058 5023 5016>,
			<5983 5524 5236 5059 5023 5017>,
			<5971 5522 5234 5059 5024 5017>,
			<5954 5518 5230 5059 5025 5018>,
			<5951 5513 5227 5060 5025 5019>,
			<5952 5506 5224 5062 5026 5020>,
			<5953 5499 5223 5063 5028 5021>,
			<5945 5490 5223 5065 5029 5022>,
			<5933 5484 5224 5067 5031 5023>,
			<5926 5488 5225 5069 5032 5024>,
			<5921 5502 5230 5073 5034 5026>,
			<5913 5507 5233 5077 5037 5027>,
			<5870 5492 5237 5081 5040 5030>,
			<5815 5470 5240 5087 5043 5033>,
			<5793 5454 5235 5093 5049 5037>,
			<5782 5439 5222 5099 5055 5043>,
			<5772 5426 5209 5099 5055 5043>,
			<5759 5415 5193 5082 5045 5035>,
			<5750 5405 5180 5064 5033 5026>,
			<5748 5397 5173 5057 5027 5020>,
			<5748 5390 5169 5052 5022 5016>,
			<5749 5383 5167 5052 5021 5015>,
			<5765 5374 5165 5052 5022 5016>,
			<5788 5370 5165 5053 5022 5016>,
			<5809 5376 5165 5054 5024 5017>,
			<5830 5392 5165 5057 5026 5019>,
			<5854 5410 5164 5059 5029 5021>,
			<5881 5433 5160 5062 5031 5023>,
			<5911 5460 5159 5064 5034 5026>,
			<5943 5490 5162 5066 5036 5029>,
			<5977 5525 5169 5067 5037 5031>,
			<6012 5562 5179 5066 5036 5029>,
			<6049 5605 5192 5062 5031 5023>,
			<6086 5650 5206 5058 5027 5020>,
			<6120 5699 5222 5056 5025 5020>,
			<6153 5750 5240 5055 5024 5021>,
			<6183 5800 5260 5056 5025 5023>,
			<6208 5852 5282 5060 5028 5024>,
			<6237 5910 5307 5062 5028 5023>,
			<6273 5972 5333 5063 5023 5018>,
			<6326 6001 5326 5058 5018 5012>,
			<6353 6065 5354 5064 5026 5022>,
			<6420 6134 5383 5069 5033 5032>,
			<6506 6218 5427 5076 5044 5043>,
			<6636 6300 5482 5087 5055 5051>,
			<6850 6415 5544 5091 5050 5044>,
			<7510 6578 5620 5080 5034 5027>,
			<9359 7097 5759 5079 5031 5026>,
			<14518 9310 6085 5091 5036 5030>,
			<33259 19500 6907 5113 5047 5040>,
			<33259 19500 6907 5113 5047 5040>,
			<33259 19500 6907 5113 5047 5040>;
	};

};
